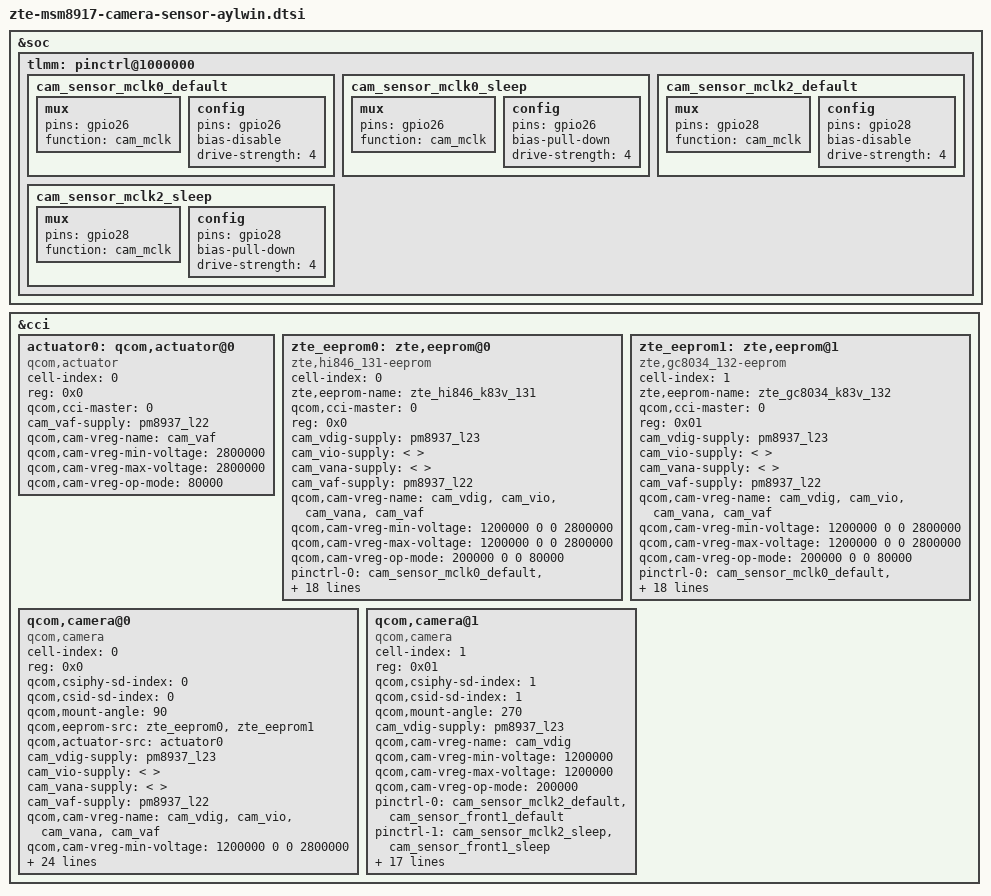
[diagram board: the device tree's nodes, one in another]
/*
 * Copyright (c) 2015-2016, The Linux Foundation. All rights reserved.
 *
 * This program is free software; you can redistribute it and/or modify
 * it under the terms of the GNU General Public License version 2 and
 * only version 2 as published by the Free Software Foundation.
 *
 * This program is distributed in the hope that it will be useful,
 * but WITHOUT ANY WARRANTY; without even the implied warranty of
 * MERCHANTABILITY or FITNESS FOR A PARTICULAR PURPOSE.  See the
 * GNU General Public License for more details.
 */
&soc {
	tlmm: pinctrl@1000000 {
			 /*sensors */
			cam_sensor_mclk0_default: cam_sensor_mclk0_default {
				/* MCLK0 */
				mux {
					/* CLK, DATA */
					pins = "gpio26";
					function = "cam_mclk";
				};

				config {
					pins = "gpio26";
					bias-disable; /* No PULL */
					drive-strength = <4>; /* 4 MA */
				};
			};

			cam_sensor_mclk0_sleep: cam_sensor_mclk0_sleep {
				/* MCLK0 */
				mux {
					/* CLK, DATA */
					pins = "gpio26";
					function = "cam_mclk";
				};

				config {
					pins = "gpio26";
					bias-pull-down; /* PULL DOWN */
					drive-strength = <4>; /* 4 MA */
				};
			};

			cam_sensor_mclk2_default: cam_sensor_mclk2_default {
				/* MCLK2 */
				mux {
					/* CLK, DATA */
					pins = "gpio28";
					function = "cam_mclk";
				};

				config {
					pins = "gpio28";
					bias-disable; /* No PULL */
					drive-strength = <4>; /* 4 MA */
				};
			};

			cam_sensor_mclk2_sleep: cam_sensor_mclk2_sleep {
				/* MCLK2 */
				mux {
					/* CLK, DATA */
					pins = "gpio28";
					function = "cam_mclk";
				};

				config {
					pins = "gpio28";
					bias-pull-down; /* PULL DOWN */
					drive-strength = <4>; /* 4 MA */
				};
			};
	};
};
&cci {
	actuator0: qcom,actuator@0 {
		cell-index = <0>;
		reg = <0x0>;
		compatible = "qcom,actuator";
		qcom,cci-master = <0>;
		cam_vaf-supply = <&pm8937_l22>;
		qcom,cam-vreg-name = "cam_vaf";
		qcom,cam-vreg-min-voltage = <2800000>;
		qcom,cam-vreg-max-voltage = <2800000>;
		qcom,cam-vreg-op-mode = <80000>;
	};
	zte_eeprom0: zte,eeprom@0 {
		cell-index = <0>;
		compatible = "zte,hi846_131-eeprom";
		zte,eeprom-name = "zte_hi846_k83v_131";
		qcom,cci-master = <0>;
		reg = <0x0>;
		cam_vdig-supply = <&pm8937_l23>;
		cam_vio-supply = < >;
		cam_vana-supply = < >;
		cam_vaf-supply = <&pm8937_l22>;
		qcom,cam-vreg-name = "cam_vdig","cam_vio","cam_vana","cam_vaf";
		qcom,cam-vreg-min-voltage = <1200000 0 0 2800000>;
		qcom,cam-vreg-max-voltage = <1200000 0 0 2800000>;
		qcom,cam-vreg-op-mode = <200000 0 0 80000>;
		pinctrl-names = "cam_default", "cam_suspend";
		pinctrl-0 = <&cam_sensor_mclk0_default
				&cam_sensor_rear_default
				&cam_sensor_rear_vdig>;
		pinctrl-1 = <&cam_sensor_mclk0_sleep &cam_sensor_rear_sleep
				&cam_sensor_rear_vdig_sleep>;
		gpios = <&tlmm 26 0>,
			<&tlmm 36 0>,
			<&tlmm 35 0>,
			<&tlmm 129 0>,
			<&tlmm 68 0>;
		qcom,gpio-reset = <1>;
		qcom,gpio-standby = <2>;
		qcom,gpio-vana = <3>;
		qcom,gpio-vio = <4>;
		qcom,gpio-req-tbl-num = <0 1 2 3 4>;
		qcom,gpio-req-tbl-flags = <1 0 0 0 0>;
		qcom,gpio-req-tbl-label = "CAMIF_MCLK0-aylwin",
			"CAM_RESET0",
			"CAM_STANDBY0",
			"CAM_VANA",
			"CAM_VIO";
		status = "ok";
		clocks = <&clock_gcc clk_mclk0_clk_src>,
				<&clock_gcc clk_gcc_camss_mclk0_clk>;
		clock-names = "cam_src_clk", "cam_clk";
		qcom,clock-rates = <24000000 0>;
	};
	zte_eeprom1: zte,eeprom@1 {
		cell-index = <1>;
		compatible = "zte,gc8034_132-eeprom";
		zte,eeprom-name = "zte_gc8034_k83v_132";
		qcom,cci-master = <0>;
		reg = <0x01>;
		cam_vdig-supply = <&pm8937_l23>;
		cam_vio-supply = < >;
		cam_vana-supply = < >;
		cam_vaf-supply = <&pm8937_l22>;
		qcom,cam-vreg-name = "cam_vdig","cam_vio","cam_vana","cam_vaf";
		qcom,cam-vreg-min-voltage = <1200000 0 0 2800000>;
		qcom,cam-vreg-max-voltage = <1200000 0 0 2800000>;
		qcom,cam-vreg-op-mode = <200000 0 0 80000>;
		pinctrl-names = "cam_default", "cam_suspend";
		pinctrl-0 = <&cam_sensor_mclk0_default
				&cam_sensor_rear_default
				&cam_sensor_rear_vdig>;
		pinctrl-1 = <&cam_sensor_mclk0_sleep &cam_sensor_rear_sleep
				&cam_sensor_rear_vdig_sleep>;
		gpios = <&tlmm 26 0>,
			<&tlmm 36 0>,
			<&tlmm 35 0>,
			<&tlmm 129 0>,
			<&tlmm 68 0>;
		qcom,gpio-reset = <1>;
		qcom,gpio-standby = <2>;
		qcom,gpio-vana = <3>;
		qcom,gpio-vio = <4>;
		qcom,gpio-req-tbl-num = <0 1 2 3 4>;
		qcom,gpio-req-tbl-flags = <1 0 0 0 0>;
		qcom,gpio-req-tbl-label = "CAMIF_MCLK0-aylwin",
			"CAM_RESET0",
			"CAM_STANDBY0",
			"CAM_VANA",
			"CAM_VIO";
		status = "ok";
		clocks = <&clock_gcc clk_mclk0_clk_src>,
				<&clock_gcc clk_gcc_camss_mclk0_clk>;
		clock-names = "cam_src_clk", "cam_clk";
		qcom,clock-rates = <24000000 0>;
	};
	qcom,camera@0 {
		cell-index = <0>;
		compatible = "qcom,camera";
		reg = <0x0>;
		qcom,csiphy-sd-index = <0>;
		qcom,csid-sd-index = <0>;
		qcom,mount-angle = <90>;
		qcom,eeprom-src = <&zte_eeprom0 &zte_eeprom1>;
		qcom,actuator-src = <&actuator0>;
		cam_vdig-supply = <&pm8937_l23>;
		cam_vio-supply = < >;
		cam_vana-supply = < >;
		cam_vaf-supply = <&pm8937_l22>;
		qcom,cam-vreg-name = "cam_vdig","cam_vio","cam_vana","cam_vaf";
		qcom,cam-vreg-min-voltage = <1200000 0 0 2800000>;
		qcom,cam-vreg-max-voltage = <1200000 0 0 2800000>;
		qcom,cam-vreg-op-mode = <200000 0 0 80000>;
		pinctrl-names = "cam_default", "cam_suspend";
		pinctrl-0 = <&cam_sensor_mclk0_default
				&cam_sensor_rear_default
				&cam_sensor_rear_vdig>;
		pinctrl-1 = <&cam_sensor_mclk0_sleep &cam_sensor_rear_sleep
				&cam_sensor_rear_vdig_sleep>;
		gpios = <&tlmm 26 0>,
			<&tlmm 36 0>,
			<&tlmm 35 0>,
			<&tlmm 129 0>,
			<&tlmm 68 0>;
		qcom,gpio-reset = <1>;
		qcom,gpio-standby = <2>;
		qcom,gpio-vana = <3>;
		qcom,gpio-vio = <4>;
		qcom,gpio-req-tbl-num = <0 1 2 3 4>;
		qcom,gpio-req-tbl-flags = <1 0 0 0 0>;
		qcom,gpio-req-tbl-label = "CAMIF_MCLK0-aylwin",
			"CAM_RESET0",
			"CAM_STANDBY0",
			"CAM_VANA",
			"CAM_VIO";
		qcom,sensor-position = <0>;
		qcom,sensor-mode = <0>;
		qcom,cci-master = <0>;
		status = "ok";
		clocks = <&clock_gcc clk_mclk0_clk_src>,
				<&clock_gcc clk_gcc_camss_mclk0_clk>;
		clock-names = "cam_src_clk", "cam_clk";
		qcom,clock-rates = <24000000 0>;
	};
	qcom,camera@1 {
		cell-index = <1>;
		compatible = "qcom,camera";
		reg = <0x01>;
		qcom,csiphy-sd-index = <1>;
		qcom,csid-sd-index = <1>;
		qcom,mount-angle = <270>;
		cam_vdig-supply = <&pm8937_l23>;
		qcom,cam-vreg-name = "cam_vdig";
		qcom,cam-vreg-min-voltage = <1200000>;
		qcom,cam-vreg-max-voltage = <1200000>;
		qcom,cam-vreg-op-mode = <200000>;
		//qcom,gpio-no-mux = <0>;
		pinctrl-names = "cam_default", "cam_suspend";
		pinctrl-0 = <&cam_sensor_mclk2_default
				&cam_sensor_front1_default >;
		pinctrl-1 = <&cam_sensor_mclk2_sleep
				&cam_sensor_front1_sleep >;
		gpios = <&tlmm 28 0>,
			<&tlmm 40 0>,
			<&tlmm 39 0>,
			<&tlmm 96 0>,
			<&tlmm 68 0>;
		qcom,gpio-reset = <1>;
		qcom,gpio-standby = <2>;
		qcom,gpio-vana = <3>;
		qcom,gpio-vio = <4>;
		qcom,gpio-req-tbl-num = <0 1 2 3 4>;
		qcom,gpio-req-tbl-flags = <1 0 0 0 0>;
		qcom,gpio-req-tbl-label = "CAMIF_MCLK1_aylwin_front",
					  "CAM_RESET1",
					  "CAM_STANDBY1",
					  "CAM_VANA",
					  "CAM_VIO";
		qcom,sensor-position = <1>;
		qcom,sensor-mode = <1>;
		qcom,cci-master = <0>;
		status = "ok";
		clocks = <&clock_gcc clk_mclk2_clk_src>,
			<&clock_gcc clk_gcc_camss_mclk2_clk>;
		clock-names = "cam_src_clk", "cam_clk";
		qcom,clock-rates = <24000000 0>;
	};
};
